# MSP432P4011 register map
Vendor: Texas Instruments; File version: 3.230
CPU: 
Registers are 32-bit, read-write, reset 0x0 unless marked. A register's access mark holds for its fields unless they carry their own. Offsets are from the block's base; [hi:lo] are bit positions.

## AES256
Base 0x40003C00
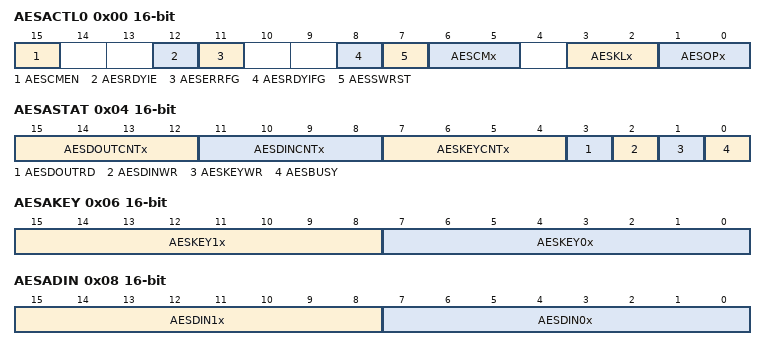
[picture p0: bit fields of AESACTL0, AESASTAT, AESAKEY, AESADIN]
0x00 AESACTL0 16-bit — AES Accelerator Control Register 0
  [15] AESCMEN — AES cipher mode enable
    0=No DMA triggers are generated; 1=DMA ciphermode support operation is enabled and the corresponding DMA triggers are generated
  [12] AESRDYIE — AES ready interrupt enable
    0=Interrupt disabled; 1=Interrupt enabled
  [11] AESERRFG — AES error flag
    0=No error; 1=Error occurred
  [8] AESRDYIFG — AES ready interrupt flag
    0=No interrupt pending; 1=Interrupt pending
  [7] AESSWRST — AES software reset
    0=No reset; 1=Reset AES accelerator module
  [6:5] AESCMx — AES cipher mode select
    0=ECB; 1=CBC; 2=OFB; 3=CFB
  [3:2] AESKLx — AES key length
    0=AES128. The key size is 128 bit; 1=AES192. The key size is 192 bit.; 2=AES256. The key size is 256 bit
  [1:0] AESOPx — AES operation
    0=Encryption; 1=Decryption. The provided key is the same key used for encryption; 2=Generate first round key required for decryption; 3=Decryption. The provided key is the first round key required for decryption
0x02 AESACTL1 16-bit — AES Accelerator Control Register 1
  [7:0] AESBLKCNTx — Cipher Block Counter
0x04 AESASTAT 16-bit — AES Accelerator Status Register
  [15:12] AESDOUTCNTx ro — Bytes read via AESADOUT
  [11:8] AESDINCNTx ro — Bytes written via AESADIN, AESAXDIN or AESAXIN
  [7:4] AESKEYCNTx ro — Bytes written via AESAKEY for AESKLx=00, half-words written via AESAKEY
  [3] AESDOUTRD ro — All 16 bytes read from AESADOUT
    0=Not all bytes read; 1=All bytes read
  [2] AESDINWR — All 16 bytes written to AESADIN, AESAXDIN or AESAXIN
    0=Not all bytes written; 1=All bytes written
  [1] AESKEYWR — All 16 bytes written to AESAKEY
    0=Not all bytes written; 1=All bytes written
  [0] AESBUSY — AES accelerator module busy
    0=Not busy; 1=Busy
0x06 AESAKEY 16-bit wo — AES Accelerator Key Register
  [15:8] AESKEY1x — AES key byte n+1 when AESAKEY is written as half-word
  [7:0] AESKEY0x — AES key byte n when AESAKEY is written as half-word
0x08 AESADIN 16-bit wo — AES Accelerator Data In Register
  [15:8] AESDIN1x — AES data in byte n+1 when AESADIN is written as half-word
  [7:0] AESDIN0x — AES data in byte n when AESADIN is written as half-word
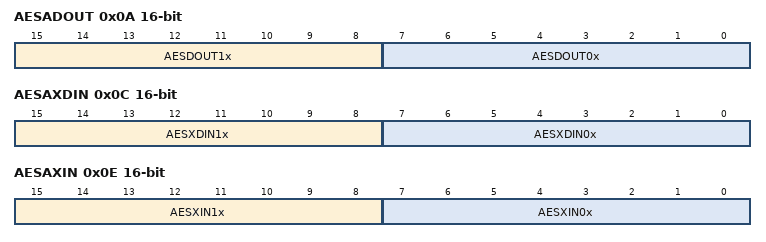
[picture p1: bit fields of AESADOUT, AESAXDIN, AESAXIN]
0x0A AESADOUT 16-bit wo — AES Accelerator Data Out Register
  [15:8] AESDOUT1x — AES data out byte n+1 when AESADOUT is read as half-word
  [7:0] AESDOUT0x — AES data out byte n when AESADOUT is read as half-word
0x0C AESAXDIN 16-bit wo — AES Accelerator XORed Data In Register
  [15:8] AESXDIN1x — AES data in byte n+1 when AESAXDIN is written as half-word
  [7:0] AESXDIN0x — AES data in byte n when AESAXDIN is written as half-word
0x0E AESAXIN 16-bit wo — AES Accelerator XORed Data In Register
  [15:8] AESXIN1x — AES data in byte n+1 when AESAXIN is written as half-word
  [7:0] AESXIN0x — AES data in byte n when AESAXIN is written as half-word

## CRC32
Base 0x40004000
0x00 CRC32DI 16-bit — Data Input for CRC32 Signature Computation
  [15:0] CRC32DI — Data input register
0x04 CRC32DIRB 16-bit — Data In Reverse for CRC32 Computation
  [15:0] CRC32DIRB — Data input register reversed
0x08 CRC32INIRES_LO 16-bit — CRC32 Initialization and Result, lower 16 bits
  [15:0] CRC32INIRES_LO — CRC32 initialization and result, lower 16 bits
0x0A CRC32INIRES_HI 16-bit — CRC32 Initialization and Result, upper 16 bits
  [15:0] CRC32INIRES_HI — CRC32 initialization and result, upper 16 bits
0x0C CRC32RESR_LO 16-bit reset 0xFFFF — CRC32 Result Reverse, lower 16 bits
  [15:0] CRC32RESR_LO — CRC32 reverse result, lower 16 bits
0x0E CRC32RESR_HI 16-bit reset 0xFFFF — CRC32 Result Reverse, Upper 16 bits
  [15:0] CRC32RESR_HI — CRC32 reverse result, upper 16 bits
0x10 CRC16DI 16-bit — Data Input for CRC16 computation
  [15:0] CRC16DI — CRC16 data in
0x14 CRC16DIRB 16-bit — CRC16 Data In Reverse
  [15:0] CRC16DIRB — CRC16 data in reverse byte
0x18 CRC16INIRES 16-bit reset 0xFFFF — CRC16 Initialization and Result register
  [15:0] CRC16INIRES — CRC16 initialization and result
0x1E CRC16RESR 16-bit reset 0xFFFF — CRC16 Result Reverse
  [15:0] CRC16RESR — CRC16 reverse result
